AUTOSAR XML (schema 4-2-1)
standard types defined: dtRef_const_VOID, dtRef_VOID, boolean, float32, float64, sint16, sint16_least, sint32, sint32_least, sint64, sint8, sint8_least, uint16, uint16_least, uint32, uint32_least, uint64, uint8, uint8_least, boolean_CompuMethod, boolean_DataConstr, float32_DataConstr, float64_DataConstr, sint16_DataConstr, sint16_least_DataConstr, sint32_DataConstr, sint32_least_DataConstr, sint64_DataConstr, sint8_DataConstr, sint8_least_DataConstr, uint16_DataConstr, uint16_least_DataConstr, uint32_DataConstr, uint32_least_DataConstr, uint64_DataConstr, uint8_DataConstr, uint8_least_DataConstr
package /CompuMethod
  compu method CM_ECU_State: identical
  compu method CM_ECU_AliveCnt: identical
  compu method CM_Temperature: phys=raw-40
  compu method CM_SupplyVoltage: phys=raw*0.01
  compu method CM_FaultFlags: identical
  compu method CM_LedCmd: identical
  compu method CM_TargetMode: identical
  compu method CM_Cmd_AliveCnt: identical
  compu method CM_PwmDuty: phys=raw*0.5
  compu method CM_Cmd_Crc8: identical
  compu method CM_FaultCode: identical
  compu method CM_FaultActive: identical
package /DataConstr
  range DC_ECU_State: phys 0..15
  range DC_ECU_AliveCnt: phys 0..15
  range DC_Temperature: phys -40..215
  range DC_SupplyVoltage: phys 0..655.35
  range DC_FaultFlags: phys 0..255
  range DC_LedCmd: phys 0..1
  range DC_TargetMode: phys 0..7
  range DC_Cmd_AliveCnt: phys 0..15
  range DC_PwmDuty: phys 0..100
  range DC_Cmd_Crc8: phys 0..255
  range DC_FaultCode: phys 0..255
  range DC_FaultActive: phys 0..1
package /PortInterfaces
  4 x sender receiver interface:
    If_EcuStatus
      5 x data:
        ECU_State: type=uint4
        ECU_AliveCnt: type=uint4
        Temperature: type=uint8
        SupplyVoltage: type=uint16
        FaultFlags: type=uint8
    If_CmdControl
      5 x data:
        LedCmd: type=boolean
        TargetMode: type=uint8
        Cmd_AliveCnt: type=uint8
        PwmDuty: type=uint8
        Cmd_Crc8: type=uint8
    If_FaultEvent
      data FaultCode: type=uint8
      data FaultActive: type=uint1
    If_IoOut
      data LedState: type=boolean
      data PwmDuty: type=uint8
package /ComponentTypes
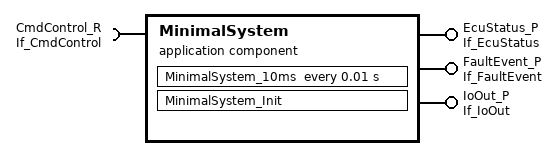
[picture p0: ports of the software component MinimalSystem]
  application sw component type MinimalSystem
    require port CmdControl_R: required-interface=If_CmdControl
      required-com-specs:
        data-element=LedCmd, init-value=0
        data-element=TargetMode, init-value=0
        data-element=Cmd_AliveCnt, init-value=0
        data-element=If_CmdControl/PwmDuty, init-value=0
        data-element=Cmd_Crc8, init-value=0
    provide port EcuStatus_P: provided-interface=If_EcuStatus
      provided-com-specs:
        data-element=ECU_State, init-value=0
        data-element=ECU_AliveCnt, init-value=0
        data-element=Temperature, init-value=0
        data-element=SupplyVoltage, init-value=0
        data-element=FaultFlags, init-value=0
    provide port FaultEvent_P: provided-com-specs=[{data-element=FaultCode, init-value=0}, {data-element=FaultActive, init-value=0}], provided-interface=If_FaultEvent
    provide port IoOut_P: provided-com-specs=[{data-element=LedState, init-value=0}, {data-element=If_IoOut/PwmDuty, init-value=0}], provided-interface=If_IoOut
    behavior MinimalSystem_IB
      init event Ev_Init: start-on-event=MinimalSystem_Init
      timing event Ev_10ms: start-on-event=MinimalSystem_10ms, period=0.01
      runnable MinimalSystem_Init
      runnable MinimalSystem_10ms
        data-read-access:
          5 x access:
            REC_CmdControl_R_LedCmd: accessed-variable=CmdControl_R.LedCmd
            REC_CmdControl_R_TargetMode: accessed-variable=CmdControl_R.TargetMode
            REC_CmdControl_R_PwmDuty: accessed-variable=CmdControl_R.PwmDuty
            REC_CmdControl_R_Cmd_AliveCnt: accessed-variable=CmdControl_R.Cmd_AliveCnt
            REC_CmdControl_R_Cmd_Crc8: accessed-variable=CmdControl_R.Cmd_Crc8
        data-write-access:
          9 x access:
            SND_IoOut_P_LedState: accessed-variable=IoOut_P.LedState
            SND_IoOut_P_PwmDuty: accessed-variable=IoOut_P.PwmDuty
            SND_FaultEvent_P_FaultCode: accessed-variable=FaultEvent_P.FaultCode
            SND_FaultEvent_P_FaultActive: accessed-variable=FaultEvent_P.FaultActive
            SND_EcuStatus_P_ECU_State: accessed-variable=EcuStatus_P.ECU_State
            SND_EcuStatus_P_ECU_AliveCnt: accessed-variable=EcuStatus_P.ECU_AliveCnt
            SND_EcuStatus_P_Temperature: accessed-variable=EcuStatus_P.Temperature
            SND_EcuStatus_P_SupplyVoltage: accessed-variable=EcuStatus_P.SupplyVoltage
            SND_EcuStatus_P_FaultFlags: accessed-variable=EcuStatus_P.FaultFlags
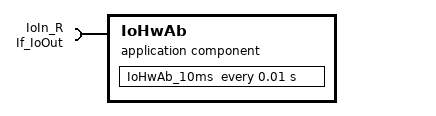
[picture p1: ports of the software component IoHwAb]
  application sw component type IoHwAb
    require port IoIn_R: required-com-specs=[{data-element=LedState, init-value=0}, {data-element=If_IoOut/PwmDuty, init-value=0}], required-interface=If_IoOut
    behavior IoHwAb_IB
      timing event Ev_IoHwAb_10ms: start-on-event=IoHwAb_10ms, period=0.01
      runnable IoHwAb_10ms
        data-read-access:
          access REC_IoIn_R_LedState: accessed-variable=IoIn_R.LedState
          access REC_IoIn_R_PwmDuty: accessed-variable=IoIn_R.PwmDuty
  swc implementation MinimalSystem_Impl: behavior=MinimalSystem_IB
  swc implementation IoHwAb_Impl: behavior=IoHwAb_IB
package /DataTypes/BaseTypes
  base type uint4: base-type-size=4, native-declaration=uint8, category=FIXED_LENGTH, array-size=4
  base type uint1: base-type-size=1, native-declaration=uint8, category=FIXED_LENGTH, array-size=1
package /DataTypes/ImplTypes
  impl type uint4: category=VALUE, base-type=uint4
  impl type uint1: category=VALUE, base-type=uint1
